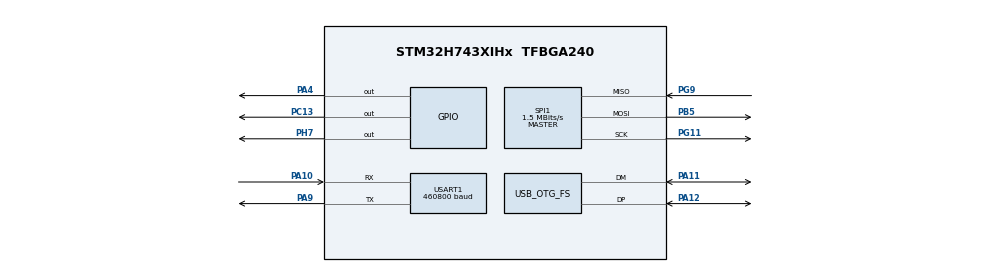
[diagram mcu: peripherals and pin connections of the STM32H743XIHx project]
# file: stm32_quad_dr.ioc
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CORTEX_M7.default_mode_Activation=1
Dma.Request0=TIM3_UP
Dma.TIM3_UP.0.Direction=DMA_MEMORY_TO_PERIPH
Dma.TIM3_UP.0.EventEnable=DISABLE
Dma.TIM3_UP.0.FIFOMode=DMA_FIFOMODE_DISABLE
Dma.TIM3_UP.0.Instance=DMA1_Stream0
Dma.TIM3_UP.0.MemDataAlignment=DMA_MDATAALIGN_WORD
Dma.TIM3_UP.0.MemInc=DMA_MINC_ENABLE
Dma.TIM3_UP.0.Mode=DMA_NORMAL
Dma.TIM3_UP.0.PeriphDataAlignment=DMA_PDATAALIGN_WORD
Dma.TIM3_UP.0.PeriphInc=DMA_PINC_DISABLE
Dma.TIM3_UP.0.Polarity=HAL_DMAMUX_REQ_GEN_RISING
Dma.TIM3_UP.0.Priority=DMA_PRIORITY_HIGH
Dma.TIM3_UP.0.RequestNumber=1
Dma.TIM3_UP.0.SignalID=NONE
Dma.TIM3_UP.0.SyncEnable=DISABLE
Dma.TIM3_UP.0.SyncPolarity=HAL_DMAMUX_SYNC_NO_EVENT
Dma.TIM3_UP.0.SyncRequestNumber=1
Dma.TIM3_UP.0.SyncSignalID=NONE
FREERTOS.Tasks01=defaultTask,24,512,StartDefaultTask,Default,NULL,Dynamic,NULL,NULL
FREERTOS.configCHECK_FOR_STACK_OVERFLOW=2
FREERTOS.configENABLE_FPU=1
FREERTOS.configTOTAL_HEAP_SIZE=65536
FREERTOS.configUSE_MALLOC_FAILED_HOOK=1
FREERTOS.configUSE_NEWLIB_REENTRANT=1
Mcu.Family=STM32H7
Mcu.Name=STM32H743XIHx
Mcu.Package=TFBGA240
NVIC.DMA1_Stream0_IRQn=true\:5\:0\:false\:false\:true\:true\:false\:true\:true
NVIC.OTG_FS_IRQn=true\:5\:0\:false\:false\:true\:true\:false\:true\:true
NVIC.PriorityGroup=NVIC_PRIORITYGROUP_4
NVIC.TIM6_DAC_IRQn=true\:15\:0\:false\:false\:true\:false\:false\:true\:true
NVIC.TimeBase=TIM6_DAC_IRQn
NVIC.TimeBaseIP=TIM6
NVIC.USART1_IRQn=true\:5\:0\:false\:false\:true\:true\:true\:true\:true
PA10.Mode=Asynchronous
PA10.Signal=USART1_RX
PA11.Mode=Device_Only
PA11.Signal=USB_OTG_FS_DM
PA12.Mode=Device_Only
PA12.Signal=USB_OTG_FS_DP
PA4.PinState=GPIO_PIN_SET
PA4.Signal=GPIO_Output
PA6.GPIO_Speed=GPIO_SPEED_FREQ_VERY_HIGH
PA6.Signal=S_TIM3_CH1
PA7.GPIO_Speed=GPIO_SPEED_FREQ_VERY_HIGH
PA7.Signal=S_TIM3_CH2
PA9.Mode=Asynchronous
PA9.Signal=USART1_TX
PB0.GPIO_Speed=GPIO_SPEED_FREQ_VERY_HIGH
PB0.Signal=S_TIM3_CH3
PB1.GPIO_Speed=GPIO_SPEED_FREQ_VERY_HIGH
PB1.Signal=S_TIM3_CH4
PB5.GPIO_Speed=GPIO_SPEED_FREQ_VERY_HIGH
PB5.Mode=Full_Duplex_Master
PB5.Signal=SPI1_MOSI
PC13.Signal=GPIO_Output
PG11.GPIO_Speed=GPIO_SPEED_FREQ_VERY_HIGH
PG11.Mode=Full_Duplex_Master
PG11.Signal=SPI1_SCK
PG9.GPIO_Speed=GPIO_SPEED_FREQ_VERY_HIGH
PG9.Mode=Full_Duplex_Master
PG9.Signal=SPI1_MISO
PH0-OSC_IN\ (PH0).Mode=HSE-External-Oscillator
PH0-OSC_IN\ (PH0).Signal=RCC_OSC_IN
PH1-OSC_OUT\ (PH1).Mode=HSE-External-Oscillator
PH1-OSC_OUT\ (PH1).Signal=RCC_OSC_OUT
PH7.Signal=GPIO_Output
ProjectManager.HeapSize=0x200
ProjectManager.StackSize=0x400
ProjectManager.TargetToolchain=STM32CubeIDE
RCC.ADCFreq_Value=50390625
RCC.APB1Freq_Value=30000000
RCC.APB2Freq_Value=30000000
RCC.APB3Freq_Value=120000000
RCC.APB4Freq_Value=120000000
RCC.CortexFreq_Value=120000000
RCC.D2PPRE1=RCC_APB1_DIV4
RCC.D2PPRE2=RCC_APB2_DIV4
RCC.DIVM1=5
RCC.DIVN1=48
RCC.DIVQ1=5
RCC.HCLKFreq_Value=120000000
RCC.PLL2FRACN=0
RCC.PLL3FRACN=0
RCC.PLLFRACN=0
RCC.SYSCLKFreq_VALUE=120000000
RCC.SYSCLKSource=RCC_SYSCLKSOURCE_PLLCLK
RCC.USBFreq_Value=48000000
SH.S_TIM3_CH1.0=TIM3_CH1
SH.S_TIM3_CH2.0=TIM3_CH2
SH.S_TIM3_CH3.0=TIM3_CH3
SH.S_TIM3_CH4.0=TIM3_CH4
SPI1.BaudRatePrescaler=SPI_BAUDRATEPRESCALER_32
SPI1.CalculateBaudRate=1.5 MBits/s
SPI1.DataSize=SPI_DATASIZE_8BIT
SPI1.Direction=SPI_DIRECTION_2LINES
SPI1.Mode=SPI_MODE_MASTER
SPI1.VirtualType=VM_MASTER
TIM3.Channel-PWM\ Generation1\ CH1=TIM_CHANNEL_1
TIM3.Channel-PWM\ Generation2\ CH2=TIM_CHANNEL_2
TIM3.Channel-PWM\ Generation3\ CH3=TIM_CHANNEL_3
TIM3.Channel-PWM\ Generation4\ CH4=TIM_CHANNEL_4
TIM3.Period=19999
TIM3.Prescaler=59
TIM3.Pulse-PWM\ Generation1\ CH1=1000
TIM3.Pulse-PWM\ Generation2\ CH2=1000
TIM3.Pulse-PWM\ Generation3\ CH3=1000
TIM3.Pulse-PWM\ Generation4\ CH4=1000
USART1.BaudRate=460800
USART1.VirtualMode-Asynchronous=VM_ASYNC
USB_DEVICE.CLASS_NAME_FS=CDC
USB_DEVICE.VirtualMode-CDC_FS=Cdc
USB_DEVICE.VirtualModeFS=Cdc_FS
USB_OTG_FS.VirtualMode=Device_Only
VP_FREERTOS_VS_CMSIS_V2.Mode=CMSIS_V2
VP_MEMORYMAP_VS_MEMORYMAP.Mode=CurAppReg
VP_SYS_VS_tim6.Mode=TIM6
VP_TIM3_VS_ClockSourceINT.Mode=Internal
VP_USB_DEVICE_VS_USB_DEVICE_CDC_FS.Mode=CDC_FS
board=custom

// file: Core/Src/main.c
/* USER CODE BEGIN Header */
/**
  ******************************************************************************
  * @file           : main.c
  * @brief          : Main program body
  ******************************************************************************
  * @attention
  *
  * Copyright (c) 2026 STMicroelectronics.
  * All rights reserved.
  *
  * This software is licensed under terms that can be found in the LICENSE file
  * in the root directory of this software component.
  * If no LICENSE file comes with this software, it is provided AS-IS.
  *
  ******************************************************************************
  */
/* USER CODE END Header */
#include "main.h"
#include "FreeRTOS.h"
#include "cmsis_os2.h"
#include "usb_device.h"

/* USER CODE BEGIN Includes */
#include "app.h"
#include "usbd_cdc_if.h"
/* USER CODE END Includes */

/* USER CODE BEGIN PD */
#define ICM20948_NCS_GPIO_Port GPIOA
#define ICM20948_NCS_Pin       GPIO_PIN_4

/* USER CODE END PD */

SPI_HandleTypeDef hspi1;

TIM_HandleTypeDef htim3;
DMA_HandleTypeDef hdma_tim3_up;

UART_HandleTypeDef huart1;

/* Definitions for defaultTask */
osThreadId_t defaultTaskHandle;
const osThreadAttr_t defaultTask_attributes = {
  .name = "defaultTask",
  .stack_size = 512 * 4,
  .priority = (osPriority_t) osPriorityNormal,
};

void SystemClock_Config(void);
static void MPU_Config(void);
static void MX_GPIO_Init(void);
static void MX_DMA_Init(void);
static void MX_SPI1_Init(void);
static void MX_TIM3_Init(void);
static void MX_USART1_UART_Init(void);
void StartDefaultTask(void *argument);

/* USER CODE BEGIN PFP */
void HAL_TIM_MspPostInit(TIM_HandleTypeDef *htim);
/* USER CODE END PFP */

int main(void)
{

  /* MPU Configuration--------------------------------------------------------*/
  MPU_Config();

  /* MCU Configuration--------------------------------------------------------*/

  /* Reset of all peripherals, Initializes the Flash interface and the Systick. */
  HAL_Init();

  /* Configure the system clock */
  SystemClock_Config();

  /* Initialize all configured peripherals */
  MX_GPIO_Init();
  MX_DMA_Init();
  MX_SPI1_Init();
  MX_TIM3_Init();
  MX_USART1_UART_Init();
  /* USER CODE BEGIN 2 */
  App_SetSpi(&hspi1, ICM20948_NCS_GPIO_Port, ICM20948_NCS_Pin);
  App_SetUsbTransmit(CDC_Transmit_FS);
  App_SetActivityLed(GPIOC, GPIO_PIN_13);
  App_SetMotorTimer(&htim3);
  App_SetControlUart(&huart1);
  App_Init();
  /* USER CODE END 2 */

  /* Init scheduler */
  osKernelInitialize();

  /* Create the thread(s) */
  /* creation of defaultTask */
  defaultTaskHandle = osThreadNew(StartDefaultTask, NULL, &defaultTask_attributes);

  /* Start scheduler */
  osKernelStart();

  /* We should never get here as control is now taken by the scheduler */

  /* Infinite loop */
  while (1)
  {

    /* USER CODE BEGIN 3 */
    App_Process();
  }
  /* USER CODE END 3 */
}

void SystemClock_Config(void)
{
  RCC_OscInitTypeDef RCC_OscInitStruct = {0};
  RCC_ClkInitTypeDef RCC_ClkInitStruct = {0};

  /** Supply configuration update enable
  */
  HAL_PWREx_ConfigSupply(PWR_LDO_SUPPLY);

  /** Configure the main internal regulator output voltage
  */
  __HAL_PWR_VOLTAGESCALING_CONFIG(PWR_REGULATOR_VOLTAGE_SCALE3);

  while(!__HAL_PWR_GET_FLAG(PWR_FLAG_VOSRDY)) {}

  /** Initializes the RCC Oscillators according to the specified parameters
  * in the RCC_OscInitTypeDef structure.
  */
  RCC_OscInitStruct.OscillatorType = RCC_OSCILLATORTYPE_HSE;
  RCC_OscInitStruct.HSEState = RCC_HSE_ON;
  RCC_OscInitStruct.PLL.PLLState = RCC_PLL_ON;
  RCC_OscInitStruct.PLL.PLLSource = RCC_PLLSOURCE_HSE;
  RCC_OscInitStruct.PLL.PLLM = 5;
  RCC_OscInitStruct.PLL.PLLN = 48;
  RCC_OscInitStruct.PLL.PLLP = 2;
  RCC_OscInitStruct.PLL.PLLQ = 5;
  RCC_OscInitStruct.PLL.PLLR = 2;
  RCC_OscInitStruct.PLL.PLLRGE = RCC_PLL1VCIRANGE_2;
  RCC_OscInitStruct.PLL.PLLVCOSEL = RCC_PLL1VCOWIDE;
  RCC_OscInitStruct.PLL.PLLFRACN = 0;
  if (HAL_RCC_OscConfig(&RCC_OscInitStruct) != HAL_OK)
  {
    Error_Handler();
  }

  /** Initializes the CPU, AHB and APB buses clocks
  */
  RCC_ClkInitStruct.ClockType = RCC_CLOCKTYPE_HCLK|RCC_CLOCKTYPE_SYSCLK
                              |RCC_CLOCKTYPE_PCLK1|RCC_CLOCKTYPE_PCLK2
                              |RCC_CLOCKTYPE_D3PCLK1|RCC_CLOCKTYPE_D1PCLK1;
  RCC_ClkInitStruct.SYSCLKSource = RCC_SYSCLKSOURCE_PLLCLK;
  RCC_ClkInitStruct.SYSCLKDivider = RCC_SYSCLK_DIV1;
  RCC_ClkInitStruct.AHBCLKDivider = RCC_HCLK_DIV1;
  RCC_ClkInitStruct.APB3CLKDivider = RCC_APB3_DIV1;
  RCC_ClkInitStruct.APB1CLKDivider = RCC_APB1_DIV4;
  RCC_ClkInitStruct.APB2CLKDivider = RCC_APB2_DIV4;
  RCC_ClkInitStruct.APB4CLKDivider = RCC_APB4_DIV1;

  if (HAL_RCC_ClockConfig(&RCC_ClkInitStruct, FLASH_LATENCY_2) != HAL_OK)
  {
    Error_Handler();
  }
}

static void MX_SPI1_Init(void)
{

  /* SPI1 parameter configuration*/
  hspi1.Instance = SPI1;
  hspi1.Init.Mode = SPI_MODE_MASTER;
  hspi1.Init.Direction = SPI_DIRECTION_2LINES;
  hspi1.Init.DataSize = SPI_DATASIZE_8BIT;
  hspi1.Init.CLKPolarity = SPI_POLARITY_LOW;
  hspi1.Init.CLKPhase = SPI_PHASE_1EDGE;
  hspi1.Init.NSS = SPI_NSS_SOFT;
  hspi1.Init.BaudRatePrescaler = SPI_BAUDRATEPRESCALER_32;
  hspi1.Init.FirstBit = SPI_FIRSTBIT_MSB;
  hspi1.Init.TIMode = SPI_TIMODE_DISABLE;
  hspi1.Init.CRCCalculation = SPI_CRCCALCULATION_DISABLE;
  hspi1.Init.CRCPolynomial = 0x0;
  hspi1.Init.NSSPMode = SPI_NSS_PULSE_ENABLE;
  hspi1.Init.NSSPolarity = SPI_NSS_POLARITY_LOW;
  hspi1.Init.FifoThreshold = SPI_FIFO_THRESHOLD_01DATA;
  hspi1.Init.TxCRCInitializationPattern = SPI_CRC_INITIALIZATION_ALL_ZERO_PATTERN;
  hspi1.Init.RxCRCInitializationPattern = SPI_CRC_INITIALIZATION_ALL_ZERO_PATTERN;
  hspi1.Init.MasterSSIdleness = SPI_MASTER_SS_IDLENESS_00CYCLE;
  hspi1.Init.MasterInterDataIdleness = SPI_MASTER_INTERDATA_IDLENESS_00CYCLE;
  hspi1.Init.MasterReceiverAutoSusp = SPI_MASTER_RX_AUTOSUSP_DISABLE;
  hspi1.Init.MasterKeepIOState = SPI_MASTER_KEEP_IO_STATE_DISABLE;
  hspi1.Init.IOSwap = SPI_IO_SWAP_DISABLE;
  if (HAL_SPI_Init(&hspi1) != HAL_OK)
  {
    Error_Handler();
  }

}

static void MX_TIM3_Init(void)
{

  TIM_ClockConfigTypeDef sClockSourceConfig = {0};
  TIM_MasterConfigTypeDef sMasterConfig = {0};

  htim3.Instance = TIM3;
  htim3.Init.Prescaler = 59;
  htim3.Init.CounterMode = TIM_COUNTERMODE_UP;
  htim3.Init.Period = 19999;
  htim3.Init.ClockDivision = TIM_CLOCKDIVISION_DIV1;
  htim3.Init.AutoReloadPreload = TIM_AUTORELOAD_PRELOAD_DISABLE;
  if (HAL_TIM_Base_Init(&htim3) != HAL_OK)
  {
    Error_Handler();
  }
  sClockSourceConfig.ClockSource = TIM_CLOCKSOURCE_INTERNAL;
  if (HAL_TIM_ConfigClockSource(&htim3, &sClockSourceConfig) != HAL_OK)
  {
    Error_Handler();
  }
  sMasterConfig.MasterOutputTrigger = TIM_TRGO_RESET;
  sMasterConfig.MasterSlaveMode = TIM_MASTERSLAVEMODE_DISABLE;
  if (HAL_TIMEx_MasterConfigSynchronization(&htim3, &sMasterConfig) != HAL_OK)
  {
    Error_Handler();
  }

}

static void MX_USART1_UART_Init(void)
{

  huart1.Instance = USART1;
  huart1.Init.BaudRate = 460800;
  huart1.Init.WordLength = UART_WORDLENGTH_8B;
  huart1.Init.StopBits = UART_STOPBITS_1;
  huart1.Init.Parity = UART_PARITY_NONE;
  huart1.Init.Mode = UART_MODE_TX_RX;
  huart1.Init.HwFlowCtl = UART_HWCONTROL_NONE;
  huart1.Init.OverSampling = UART_OVERSAMPLING_16;
  huart1.Init.OneBitSampling = UART_ONE_BIT_SAMPLE_DISABLE;
  huart1.Init.ClockPrescaler = UART_PRESCALER_DIV1;
  huart1.AdvancedInit.AdvFeatureInit = UART_ADVFEATURE_NO_INIT;
  if (HAL_UART_Init(&huart1) != HAL_OK)
  {
    Error_Handler();
  }
  if (HAL_UARTEx_SetTxFifoThreshold(&huart1, UART_TXFIFO_THRESHOLD_1_8) != HAL_OK)
  {
    Error_Handler();
  }
  if (HAL_UARTEx_SetRxFifoThreshold(&huart1, UART_RXFIFO_THRESHOLD_1_8) != HAL_OK)
  {
    Error_Handler();
  }
  if (HAL_UARTEx_DisableFifoMode(&huart1) != HAL_OK)
  {
    Error_Handler();
  }

}

static void MX_DMA_Init(void)
{

  /* DMA controller clock enable */
  __HAL_RCC_DMA1_CLK_ENABLE();

  /* DMA interrupt init */
  /* DMA1_Stream0_IRQn interrupt configuration */
  HAL_NVIC_SetPriority(DMA1_Stream0_IRQn, 5, 0);
  HAL_NVIC_EnableIRQ(DMA1_Stream0_IRQn);

}

static void MX_GPIO_Init(void)
{
  GPIO_InitTypeDef GPIO_InitStruct = {0};

  /* GPIO Ports Clock Enable */
  __HAL_RCC_GPIOB_CLK_ENABLE();
  __HAL_RCC_GPIOG_CLK_ENABLE();
  __HAL_RCC_GPIOA_CLK_ENABLE();
  __HAL_RCC_GPIOC_CLK_ENABLE();
  __HAL_RCC_GPIOH_CLK_ENABLE();

  /*Configure GPIO pin Output Level */
  HAL_GPIO_WritePin(GPIOC, GPIO_PIN_13, GPIO_PIN_RESET);

  /*Configure GPIO pin Output Level */
  HAL_GPIO_WritePin(GPIOA, GPIO_PIN_4, GPIO_PIN_SET);

  /*Configure GPIO pin Output Level */
  HAL_GPIO_WritePin(GPIOH, GPIO_PIN_7, GPIO_PIN_RESET);

  /*Configure GPIO pin : PC13 */
  GPIO_InitStruct.Pin = GPIO_PIN_13;
  GPIO_InitStruct.Mode = GPIO_MODE_OUTPUT_PP;
  GPIO_InitStruct.Pull = GPIO_NOPULL;
  GPIO_InitStruct.Speed = GPIO_SPEED_FREQ_LOW;
  HAL_GPIO_Init(GPIOC, &GPIO_InitStruct);

  /*Configure GPIO pin : PA4 */
  GPIO_InitStruct.Pin = GPIO_PIN_4;
  GPIO_InitStruct.Mode = GPIO_MODE_OUTPUT_PP;
  GPIO_InitStruct.Pull = GPIO_NOPULL;
  GPIO_InitStruct.Speed = GPIO_SPEED_FREQ_LOW;
  HAL_GPIO_Init(GPIOA, &GPIO_InitStruct);

  /*Configure GPIO pin : PH7 */
  GPIO_InitStruct.Pin = GPIO_PIN_7;
  GPIO_InitStruct.Mode = GPIO_MODE_OUTPUT_PP;
  GPIO_InitStruct.Pull = GPIO_NOPULL;
  GPIO_InitStruct.Speed = GPIO_SPEED_FREQ_LOW;
  HAL_GPIO_Init(GPIOH, &GPIO_InitStruct);

}

void StartDefaultTask(void *argument)
{
  /* init code for USB_DEVICE */
  MX_USB_DEVICE_Init();
  /* USER CODE BEGIN 5 */
  /* Infinite loop */
  for(;;)
  {
	  App_Process();
  }
  /* USER CODE END 5 */
}

 /* MPU Configuration */

void MPU_Config(void)
{
  MPU_Region_InitTypeDef MPU_InitStruct = {0};

  /* Disables the MPU */
  HAL_MPU_Disable();

  /** Initializes and configures the Region and the memory to be protected
  */
  MPU_InitStruct.Enable = MPU_REGION_ENABLE;
  MPU_InitStruct.Number = MPU_REGION_NUMBER0;
  MPU_InitStruct.BaseAddress = 0x0;
  MPU_InitStruct.Size = MPU_REGION_SIZE_4GB;
  MPU_InitStruct.SubRegionDisable = 0x87;
  MPU_InitStruct.TypeExtField = MPU_TEX_LEVEL0;
  MPU_InitStruct.AccessPermission = MPU_REGION_NO_ACCESS;
  MPU_InitStruct.DisableExec = MPU_INSTRUCTION_ACCESS_DISABLE;
  MPU_InitStruct.IsShareable = MPU_ACCESS_SHAREABLE;
  MPU_InitStruct.IsCacheable = MPU_ACCESS_NOT_CACHEABLE;
  MPU_InitStruct.IsBufferable = MPU_ACCESS_NOT_BUFFERABLE;

  HAL_MPU_ConfigRegion(&MPU_InitStruct);
  /* Enables the MPU */
  HAL_MPU_Enable(MPU_PRIVILEGED_DEFAULT);

}

void HAL_TIM_PeriodElapsedCallback(TIM_HandleTypeDef *htim)
{
  if (htim->Instance == TIM6)
  {
    HAL_IncTick();
  }
}

void Error_Handler(void)
{
  __disable_irq();
  while (1)
  {
  }
}
